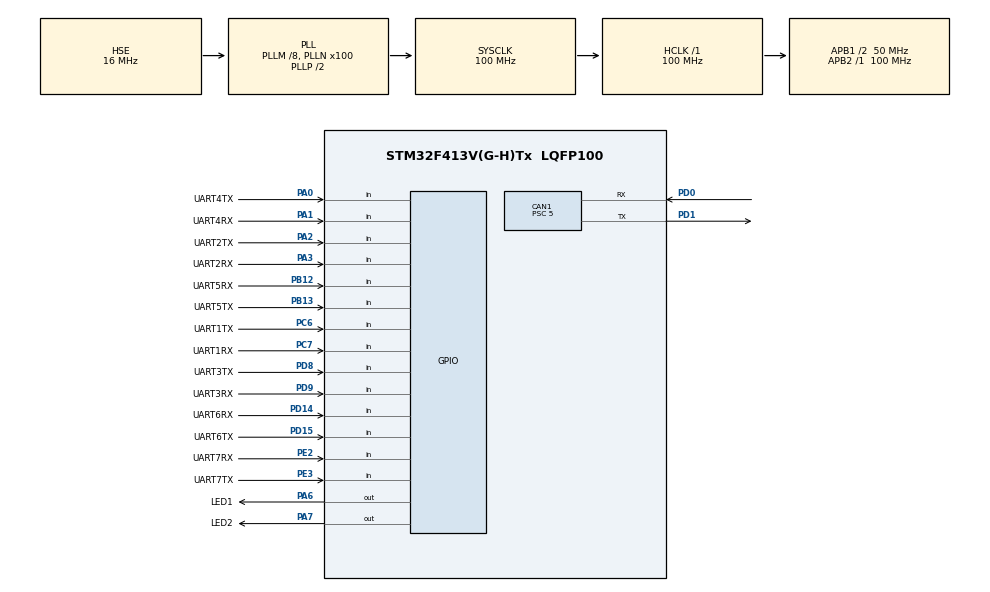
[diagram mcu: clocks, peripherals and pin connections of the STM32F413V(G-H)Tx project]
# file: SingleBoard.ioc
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CAN1.ABOM=ENABLE
CAN1.BS1=CAN_BS1_6TQ
CAN1.BS2=CAN_BS2_3TQ
CAN1.CalculateTimeBit=1000
CAN1.CalculateTimeQuantum=100.0
CAN1.Prescaler=5
CAN1.TXFP=ENABLE
FREERTOS.INCLUDE_uxTaskGetStackHighWaterMark=1
FREERTOS.Tasks01=NameGPIOIn,0,128,GPIOInDaemon,As weak,NULL,Dynamic,NULL,NULL;NameCanRx,0,128,CanRxDaemon,As weak,NULL,Dynamic,NULL,NULL;NameCanTx,0,128,CanTxDaemon,As weak,NULL,Dynamic,NULL,NULL;NameReserve,0,128,ReserveDaemon,As weak,NULL,Dynamic,NULL,NULL
FREERTOS.configTOTAL_HEAP_SIZE=25360
FREERTOS.configUSE_COUNTING_SEMAPHORES=1
FREERTOS.configUSE_PORT_OPTIMISED_TASK_SELECTION=1
Mcu.Family=STM32F4
Mcu.Name=STM32F413V(G-H)Tx
Mcu.Package=LQFP100
NVIC.CAN1_RX1_IRQn=true\:5\:0\:true\:false\:true\:true
NVIC.CAN1_TX_IRQn=true\:5\:0\:true\:false\:true\:true
NVIC.PriorityGroup=NVIC_PRIORITYGROUP_4
PA0.GPIO_Label=UART4TX
PA0.GPIO_PuPd=GPIO_PULLUP
PA0.Signal=GPIO_Input
PA1.GPIO_Label=UART4RX
PA1.GPIO_PuPd=GPIO_PULLUP
PA1.Signal=GPIO_Input
PA13.Mode=Serial_Wire
PA13.Signal=SYS_JTMS-SWDIO
PA14.Mode=Serial_Wire
PA14.Signal=SYS_JTCK-SWCLK
PA2.GPIO_Label=UART2TX
PA2.GPIO_PuPd=GPIO_PULLUP
PA2.Signal=GPIO_Input
PA3.GPIO_Label=UART2RX
PA3.GPIO_PuPd=GPIO_PULLUP
PA3.Signal=GPIO_Input
PA6.GPIO_Label=LED1
PA6.GPIO_PuPd=GPIO_PULLUP
PA6.Signal=GPIO_Output
PA7.GPIO_Label=LED2
PA7.Signal=GPIO_Output
PB12.GPIO_Label=UART5RX
PB12.GPIO_PuPd=GPIO_PULLUP
PB12.Signal=GPIO_Input
PB13.GPIO_Label=UART5TX
PB13.GPIO_PuPd=GPIO_PULLUP
PB13.Signal=GPIO_Input
PC6.GPIO_Label=UART1TX
PC6.GPIO_PuPd=GPIO_PULLUP
PC6.Signal=GPIO_Input
PC7.GPIO_Label=UART1RX
PC7.GPIO_PuPd=GPIO_PULLUP
PC7.Signal=GPIO_Input
PD0.Mode=Master
PD0.Signal=CAN1_RX
PD1.Mode=Master
PD1.Signal=CAN1_TX
PD14.GPIO_Label=UART6RX
PD14.GPIO_PuPd=GPIO_PULLUP
PD14.Signal=GPIO_Input
PD15.GPIO_Label=UART6TX
PD15.GPIO_PuPd=GPIO_PULLUP
PD15.Signal=GPIO_Input
PD8.GPIO_Label=UART3TX
PD8.GPIO_PuPd=GPIO_PULLUP
PD8.Signal=GPIO_Input
PD9.GPIO_Label=UART3RX
PD9.GPIO_PuPd=GPIO_PULLUP
PD9.Signal=GPIO_Input
PE2.GPIO_Label=UART7RX
PE2.GPIO_PuPd=GPIO_PULLUP
PE2.Signal=GPIO_Input
PE3.GPIO_Label=UART7TX
PE3.GPIO_PuPd=GPIO_PULLUP
PE3.Signal=GPIO_Input
PH0\ -\ OSC_IN.Mode=HSE-External-Oscillator
PH0\ -\ OSC_IN.Signal=RCC_OSC_IN
PH1\ -\ OSC_OUT.Mode=HSE-External-Oscillator
PH1\ -\ OSC_OUT.Signal=RCC_OSC_OUT
ProjectManager.HeapSize=0x200
ProjectManager.StackSize=0x400
ProjectManager.TargetToolchain=MDK-ARM V5
RCC.AHBFreq_Value=100000000
RCC.APB1CLKDivider=RCC_HCLK_DIV2
RCC.APB1Freq_Value=50000000
RCC.APB1TimFreq_Value=100000000
RCC.APB2Freq_Value=100000000
RCC.APB2TimFreq_Value=100000000
RCC.CortexFreq_Value=100000000
RCC.HCLKFreq_Value=100000000
RCC.HSE_VALUE=16000000
RCC.PLLM=8
RCC.PLLN=100
RCC.PLLSourceVirtual=RCC_PLLSOURCE_HSE
RCC.SYSCLKFreq_VALUE=100000000
RCC.SYSCLKSource=RCC_SYSCLKSOURCE_PLLCLK
RCC.USBFreq_Value=100000000
RCC.VCOOutputFreq_Value=200000000
VP_FREERTOS_VS_ENABLE.Mode=Enabled
board=SingleBoard

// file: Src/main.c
/**
  ******************************************************************************
  * File Name          : main.c
  * Description        : Main program body
  ******************************************************************************
  *
  * Copyright (c) 2017 STMicroelectronics International N.V.
  * All rights reserved.
  *
  * Redistribution and use in source and binary forms, with or without
  * modification, are permitted, provided that the following conditions are met:
  *
  * 1. Redistribution of source code must retain the above copyright notice,
  *    this list of conditions and the following disclaimer.
  * 2. Redistributions in binary form must reproduce the above copyright notice,
  *    this list of conditions and the following disclaimer in the documentation
  *    and/or other materials provided with the distribution.
  * 3. Neither the name of STMicroelectronics nor the names of other
  *    contributors to this software may be used to endorse or promote products
  *    derived from this software without specific written permission.
  * 4. This software, including modifications and/or derivative works of this
  *    software, must execute solely and exclusively on microcontroller or
  *    microprocessor devices manufactured by or for STMicroelectronics.
  * 5. Redistribution and use of this software other than as permitted under
  *    this license is void and will automatically terminate your rights under
  *    this license.
  *
  * THIS SOFTWARE IS PROVIDED BY STMICROELECTRONICS AND CONTRIBUTORS "AS IS"
  * AND ANY EXPRESS, IMPLIED OR STATUTORY WARRANTIES, INCLUDING, BUT NOT
  * LIMITED TO, THE IMPLIED WARRANTIES OF MERCHANTABILITY, FITNESS FOR A
  * PARTICULAR PURPOSE AND NON-INFRINGEMENT OF THIRD PARTY INTELLECTUAL PROPERTY
  * RIGHTS ARE DISCLAIMED TO THE FULLEST EXTENT PERMITTED BY LAW. IN NO EVENT
  * SHALL STMICROELECTRONICS OR CONTRIBUTORS BE LIABLE FOR ANY DIRECT, INDIRECT,
  * INCIDENTAL, SPECIAL, EXEMPLARY, OR CONSEQUENTIAL DAMAGES (INCLUDING, BUT NOT
  * LIMITED TO, PROCUREMENT OF SUBSTITUTE GOODS OR SERVICES; LOSS OF USE, DATA,
  * OR PROFITS; OR BUSINESS INTERRUPTION) HOWEVER CAUSED AND ON ANY THEORY OF
  * LIABILITY, WHETHER IN CONTRACT, STRICT LIABILITY, OR TORT (INCLUDING
  * NEGLIGENCE OR OTHERWISE) ARISING IN ANY WAY OUT OF THE USE OF THIS SOFTWARE,
  * EVEN IF ADVISED OF THE POSSIBILITY OF SUCH DAMAGE.
  *
  ******************************************************************************
  */
#include "main.h"
#include "stm32f4xx_hal.h"
#include "cmsis_os.h"
#include "can.h"
#include "gpio.h"

/* USER CODE BEGIN Includes */
#include "BspCan.h"
/* USER CODE END Includes */

/* USER CODE BEGIN PV */
/* Private variables ---------------------------------------------------------*/

/* USER CODE END PV */

void SystemClock_Config(void);
void Error_Handler(void);
void MX_FREERTOS_Init(void);

/* USER CODE BEGIN PFP */
/* Private function prototypes -----------------------------------------------*/

/* USER CODE END PFP */

/* USER CODE BEGIN 0 */

void ReserveDaemon(void const * argument)
{
  /* USER CODE BEGIN ReserveDaemon */
  /* Infinite loop */
  for(;;)
  {
    osDelay(200);
 //   HAL_GPIO_TogglePin(LED1_GPIO_Port,LED1_Pin);
//    DrvGcsSendData(testsedbuf,10);
  }
  /* USER CODE END ReserveDaemon */
}
/* USER CODE END 0 */

int main(void)
{

  /* MCU Configuration----------------------------------------------------------*/

  /* Reset of all peripherals, Initializes the Flash interface and the Systick. */
  HAL_Init();

  /* Configure the system clock */
  SystemClock_Config();

  /* Initialize all configured peripherals */
  MX_GPIO_Init();
  MX_CAN1_Init();

  /* USER CODE BEGIN 2 */
  BspCanInit();
  /* USER CODE END 2 */

  /* Call init function for freertos objects (in freertos.c) */
  MX_FREERTOS_Init();

  /* Start scheduler */
  osKernelStart();

  /* We should never get here as control is now taken by the scheduler */

  /* Infinite loop */
  while (1)
  {

  }

}

/** System Clock Configuration
*/
void SystemClock_Config(void)
{

  RCC_OscInitTypeDef RCC_OscInitStruct;
  RCC_ClkInitTypeDef RCC_ClkInitStruct;

    /**Configure the main internal regulator output voltage
    */
  __HAL_RCC_PWR_CLK_ENABLE();

  __HAL_PWR_VOLTAGESCALING_CONFIG(PWR_REGULATOR_VOLTAGE_SCALE1);

    /**Initializes the CPU, AHB and APB busses clocks
    */
  RCC_OscInitStruct.OscillatorType = RCC_OSCILLATORTYPE_HSE;
  RCC_OscInitStruct.HSEState = RCC_HSE_ON;
  RCC_OscInitStruct.PLL.PLLState = RCC_PLL_ON;
  RCC_OscInitStruct.PLL.PLLSource = RCC_PLLSOURCE_HSE;
  RCC_OscInitStruct.PLL.PLLM = 8;
  RCC_OscInitStruct.PLL.PLLN = 100;
  RCC_OscInitStruct.PLL.PLLP = RCC_PLLP_DIV2;
  RCC_OscInitStruct.PLL.PLLQ = 2;
  RCC_OscInitStruct.PLL.PLLR = 2;
  if (HAL_RCC_OscConfig(&RCC_OscInitStruct) != HAL_OK)
  {
    Error_Handler();
  }

    /**Initializes the CPU, AHB and APB busses clocks
    */
  RCC_ClkInitStruct.ClockType = RCC_CLOCKTYPE_HCLK|RCC_CLOCKTYPE_SYSCLK
                              |RCC_CLOCKTYPE_PCLK1|RCC_CLOCKTYPE_PCLK2;
  RCC_ClkInitStruct.SYSCLKSource = RCC_SYSCLKSOURCE_PLLCLK;
  RCC_ClkInitStruct.AHBCLKDivider = RCC_SYSCLK_DIV1;
  RCC_ClkInitStruct.APB1CLKDivider = RCC_HCLK_DIV2;
  RCC_ClkInitStruct.APB2CLKDivider = RCC_HCLK_DIV1;

  if (HAL_RCC_ClockConfig(&RCC_ClkInitStruct, FLASH_LATENCY_3) != HAL_OK)
  {
    Error_Handler();
  }

    /**Configure the Systick interrupt time
    */
  HAL_SYSTICK_Config(HAL_RCC_GetHCLKFreq()/1000);

    /**Configure the Systick
    */
  HAL_SYSTICK_CLKSourceConfig(SYSTICK_CLKSOURCE_HCLK);

  /* SysTick_IRQn interrupt configuration */
  HAL_NVIC_SetPriority(SysTick_IRQn, 15, 0);
}

void Error_Handler(void)
{
  while(1)
  {
  }
}

/************************ (C) COPYRIGHT STMicroelectronics *****END OF FILE****/

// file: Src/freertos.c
/**
  ******************************************************************************
  * File Name          : freertos.c
  * Description        : Code for freertos applications
  ******************************************************************************
  *
  * Copyright (c) 2017 STMicroelectronics International N.V.
  * All rights reserved.
  *
  * Redistribution and use in source and binary forms, with or without
  * modification, are permitted, provided that the following conditions are met:
  *
  * 1. Redistribution of source code must retain the above copyright notice,
  *    this list of conditions and the following disclaimer.
  * 2. Redistributions in binary form must reproduce the above copyright notice,
  *    this list of conditions and the following disclaimer in the documentation
  *    and/or other materials provided with the distribution.
  * 3. Neither the name of STMicroelectronics nor the names of other
  *    contributors to this software may be used to endorse or promote products
  *    derived from this software without specific written permission.
  * 4. This software, including modifications and/or derivative works of this
  *    software, must execute solely and exclusively on microcontroller or
  *    microprocessor devices manufactured by or for STMicroelectronics.
  * 5. Redistribution and use of this software other than as permitted under
  *    this license is void and will automatically terminate your rights under
  *    this license.
  *
  * THIS SOFTWARE IS PROVIDED BY STMICROELECTRONICS AND CONTRIBUTORS "AS IS"
  * AND ANY EXPRESS, IMPLIED OR STATUTORY WARRANTIES, INCLUDING, BUT NOT
  * LIMITED TO, THE IMPLIED WARRANTIES OF MERCHANTABILITY, FITNESS FOR A
  * PARTICULAR PURPOSE AND NON-INFRINGEMENT OF THIRD PARTY INTELLECTUAL PROPERTY
  * RIGHTS ARE DISCLAIMED TO THE FULLEST EXTENT PERMITTED BY LAW. IN NO EVENT
  * SHALL STMICROELECTRONICS OR CONTRIBUTORS BE LIABLE FOR ANY DIRECT, INDIRECT,
  * INCIDENTAL, SPECIAL, EXEMPLARY, OR CONSEQUENTIAL DAMAGES (INCLUDING, BUT NOT
  * LIMITED TO, PROCUREMENT OF SUBSTITUTE GOODS OR SERVICES; LOSS OF USE, DATA,
  * OR PROFITS; OR BUSINESS INTERRUPTION) HOWEVER CAUSED AND ON ANY THEORY OF
  * LIABILITY, WHETHER IN CONTRACT, STRICT LIABILITY, OR TORT (INCLUDING
  * NEGLIGENCE OR OTHERWISE) ARISING IN ANY WAY OUT OF THE USE OF THIS SOFTWARE,
  * EVEN IF ADVISED OF THE POSSIBILITY OF SUCH DAMAGE.
  *
  ******************************************************************************
  */

#include "FreeRTOS.h"
#include "task.h"
#include "cmsis_os.h"

/* USER CODE BEGIN Includes */
#include "main.h"
/* USER CODE END Includes */

osThreadId NameGPIOInHandle;
osThreadId NameCanRxHandle;
osThreadId NameCanTxHandle;
osThreadId NameReserveHandle;

/* USER CODE BEGIN Variables */
osMessageQId myQueue_GCSHandle;
osMessageQId myQueue_GCS_SECDHandle;
/* USER CODE END Variables */

void GPIOInDaemon(void const * argument);
void CanRxDaemon(void const * argument);
void CanTxDaemon(void const * argument);
void ReserveDaemon(void const * argument);

void MX_FREERTOS_Init(void); /* (MISRA C 2004 rule 8.1) */

/* Hook prototypes */

/* Init FreeRTOS */

void MX_FREERTOS_Init(void) {

  /* Create the thread(s) */
  /* definition and creation of NameGPIOIn */
  osThreadDef(NameGPIOIn, GPIOInDaemon, osPriorityNormal, 0, 128);
  NameGPIOInHandle = osThreadCreate(osThread(NameGPIOIn), NULL);

  /* definition and creation of NameCanRx */
  osThreadDef(NameCanRx, CanRxDaemon, osPriorityNormal, 0, 128);
  NameCanRxHandle = osThreadCreate(osThread(NameCanRx), NULL);

  /* definition and creation of NameCanTx */
  osThreadDef(NameCanTx, CanTxDaemon, osPriorityNormal, 0, 128);
  NameCanTxHandle = osThreadCreate(osThread(NameCanTx), NULL);

  /* definition and creation of NameReserve */
  osThreadDef(NameReserve, ReserveDaemon, osPriorityNormal, 0, 128);
  NameReserveHandle = osThreadCreate(osThread(NameReserve), NULL);

  /* USER CODE BEGIN RTOS_QUEUES */
  osMessageQDef(myQueue_GCS, 512, uint32_t);
  myQueue_GCSHandle = osMessageCreate(osMessageQ(myQueue_GCS), NULL);
  osMessageQDef(myQueue_GCS_SECD, 512, uint32_t);
  myQueue_GCS_SECDHandle = osMessageCreate(osMessageQ(myQueue_GCS_SECD), NULL);
  /* add queues, ... */
  /* USER CODE END RTOS_QUEUES */
}

/* GPIOInDaemon function */
__weak void GPIOInDaemon(void const * argument)
{

  for(;;)
  {
    osDelay(1);
  }
}

/* CanRxDaemon function */
__weak void CanRxDaemon(void const * argument)
{
  for(;;)
  {
    osDelay(1);
  }
}

/* CanTxDaemon function */
__weak void CanTxDaemon(void const * argument)
{
  for(;;)
  {
    osDelay(1);
  }
}

/* ReserveDaemon function */
__weak void ReserveDaemon(void const * argument)
{
  /* USER CODE BEGIN ReserveDaemon */
  /* Infinite loop */
  for(;;)
  {
    osDelay(200);
//    DrvGcsSendData(testsedbuf,10);
  }
  /* USER CODE END ReserveDaemon */
}

/************************ (C) COPYRIGHT STMicroelectronics *****END OF FILE****/
